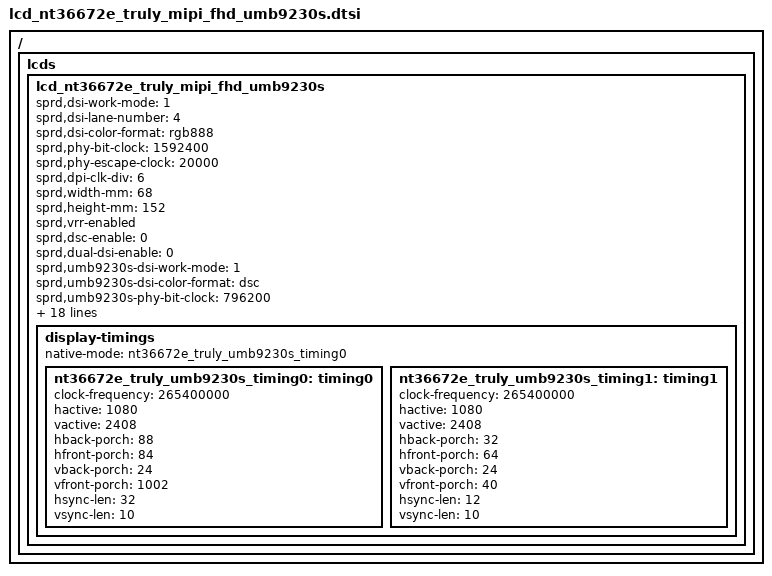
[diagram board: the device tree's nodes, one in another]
// SPDX-License-Identifier: GPL-2.0-only
/*
 * NT36672E TRULY config dtsi file for spreadtrum
 *
 * Copyright (C) 2021, Spreadtrum Communications Inc.
 */
/ {
	fragment {
		target-path = "/";
		__overlay__ {
			lcds {
				lcd_nt36672e_truly_mipi_fhd_umb9230s: lcd_nt36672e_truly_mipi_fhd_umb9230s {

					sprd,dsi-work-mode = <1>; /* video burst mode*/
					sprd,dsi-lane-number = <4>;
					sprd,dsi-color-format = "rgb888";

					sprd,phy-bit-clock = <1592400>;  /* kbps */
					sprd,phy-escape-clock = <20000>;/* kHz */

					sprd,dpi-clk-div = <6>;

					sprd,width-mm = <68>;
					sprd,height-mm = <152>;

					sprd,vrr-enabled;

					sprd,dsc-enable = <0>;
					sprd,dual-dsi-enable = <0>;

					sprd,umb9230s-dsi-work-mode = <1>; /* video burst mode*/
					sprd,umb9230s-dsi-color-format = "dsc";
					sprd,umb9230s-phy-bit-clock = <796200>;  /* kbps */
					sprd,umb9230s-dsc-enable = <1>;
					sprd,umb9230s-slice-width = <540>;
					sprd,umb9230s-slice-height = <8>;
					sprd,umb9230s-output-bpc = <8>;

					sprd,esd-check-enable = <1>;
					sprd,esd-check-mode = <0>;  // 0:Reg mode 1:TE mode
					sprd,esd-check-period = <1000>;
					sprd,esd-check-register = <0x0A>;
					sprd,esd-check-value = <0x9C>;

					sprd,reset-on-sequence = <1 15>, <0 15>, <1 15>;
					sprd,reset-off-sequence = <0 5>;

					sprd,use-gen-write;

					sprd,initial-command = [
						15 00 00 02 FF 10
						15 00 00 02 FB 01
						15 00 00 02 B0 00
						15 00 00 02 C0 03
						29 00 00 11 C1 89 28 00 08 02 00 02 0E 00 BB 00 07 0D B7 0C B7
						29 00 00 03 C2 12 18
						29 00 00 02 35 00

						15 00 00 02 FF 20
						15 00 00 02 FB 01
						15 00 00 02 01 66
						15 00 00 02 06 40
						15 00 00 02 07 38
						15 00 00 02 1B 01
						15 00 00 02 5C 90
						15 00 00 02 5E B2
						15 00 00 02 69 D1
						15 00 00 02 95 D1
						15 00 00 02 96 D1
						15 00 00 02 F2 64
						15 00 00 02 F4 64
						15 00 00 02 F6 64
						15 00 00 02 F8 64

						15 00 00 02 FF 24
						15 00 00 02 FB 01
						15 00 00 02 01 0F
						15 00 00 02 03 0C
						15 00 00 02 05 1D
						15 00 00 02 08 2F
						15 00 00 02 09 2E
						15 00 00 02 0A 2D
						15 00 00 02 0B 2C
						15 00 00 02 11 17
						15 00 00 02 12 13
						15 00 00 02 13 15
						15 00 00 02 15 14
						15 00 00 02 16 16
						15 00 00 02 17 18
						15 00 00 02 1B 01
						15 00 00 02 1D 1D
						15 00 00 02 20 2F
						15 00 00 02 21 2E
						15 00 00 02 22 2D
						15 00 00 02 23 2C
						15 00 00 02 29 17
						15 00 00 02 2A 13
						15 00 00 02 2B 15
						15 00 00 02 2F 14
						15 00 00 02 30 16
						15 00 00 02 31 18
						15 00 00 02 32 04
						15 00 00 02 34 10
						15 00 00 02 35 1F
						15 00 00 02 36 1F
						15 00 00 02 4D 19
						15 00 00 02 4E 45
						15 00 00 02 4F 45
						15 00 00 02 53 45
						15 00 00 02 71 30
						15 00 00 02 79 11
						15 00 00 02 7A 82
						15 00 00 02 7B 94
						15 00 00 02 7D 04
						15 00 00 02 80 04
						15 00 00 02 81 04
						15 00 00 02 82 13
						15 00 00 02 84 31
						15 00 00 02 85 00
						15 00 00 02 86 00
						15 00 00 02 87 00
						15 00 00 02 90 13
						15 00 00 02 92 31
						15 00 00 02 93 00
						15 00 00 02 94 00
						15 00 00 02 95 00
						15 00 00 02 9C F4
						15 00 00 02 9D 01
						15 00 00 02 A0 14
						15 00 00 02 A2 14
						15 00 00 02 A3 02
						15 00 00 02 A4 04
						15 00 00 02 A5 04
						15 00 00 02 C6 C0
						15 00 00 02 C9 00
						15 00 00 02 D9 80
						15 00 00 02 E9 02

						15 00 00 02 FF 25
						15 00 00 02 FB 01
						15 00 00 02 0F 1B
						15 00 00 02 19 E4
						15 00 00 02 21 40
						15 00 00 02 66 D8
						15 00 00 02 68 50
						15 00 00 02 69 10
						15 00 00 02 6B 00
						15 00 00 02 6D 0D
						15 00 00 02 6E 48
						15 00 00 02 72 41
						15 00 00 02 73 4A
						15 00 00 02 74 D0
						15 00 00 02 77 62
						15 00 00 02 7D 40
						15 00 00 02 7F 00
						15 00 00 02 80 04
						15 00 00 02 84 0D
						15 00 00 02 CF 80
						15 00 00 02 D6 80
						15 00 00 02 D7 80
						15 00 00 02 EF 20
						15 00 00 02 F0 84

						15 00 00 02 FF 26
						15 00 00 02 FB 01
						15 00 00 02 15 04
						15 00 00 02 81 14
						15 00 00 02 83 02
						15 00 00 02 84 03
						15 00 00 02 85 01
						15 00 00 02 86 03
						15 00 00 02 87 01
						15 00 00 02 88 06
						15 00 00 02 8A 1A
						15 00 00 02 8B 11
						15 00 00 02 8C 24
						15 00 00 02 8E 42
						15 00 00 02 8F 11
						15 00 00 02 90 11
						15 00 00 02 91 11
						15 00 00 02 9A 81
						15 00 00 02 9B 03
						15 00 00 02 9C 00
						15 00 00 02 9D 00
						15 00 00 02 9E 00

						15 00 00 02 FF 27
						15 00 00 02 FB 01
						15 00 00 02 01 68
						15 00 00 02 20 81
						15 00 00 02 21 E9
						15 00 00 02 25 82
						15 00 00 02 26 1E
						15 00 00 02 6E 00
						15 00 00 02 6F 00
						15 00 00 02 70 00
						15 00 00 02 71 00
						15 00 00 02 72 00
						15 00 00 02 75 00
						15 00 00 02 76 00
						15 00 00 02 77 00
						15 00 00 02 7D 09
						15 00 00 02 7E 67
						15 00 00 02 80 23
						15 00 00 02 82 09
						15 00 00 02 83 67
						15 00 00 02 88 01
						15 00 00 02 89 10
						15 00 00 02 A6 23
						15 00 00 02 A7 01
						15 00 00 02 B6 40

						15 00 00 02 FF 2A
						15 00 00 02 FB 01
						15 00 00 02 00 91
						15 00 00 02 03 20
						15 00 00 02 07 5A
						15 00 00 02 0A 70
						15 00 00 02 0D 40
						15 00 00 02 0E 02
						15 00 00 02 11 F0
						15 00 00 02 15 0F
						15 00 00 02 16 1A
						15 00 00 02 19 0E
						15 00 00 02 1A EE
						15 00 00 02 1B 14
						15 00 00 02 1D 36
						15 00 00 02 1E 4F
						15 00 00 02 1F 4F
						15 00 00 02 20 4F
						15 00 00 02 28 F7
						15 00 00 02 29 06
						15 00 00 02 2A 03
						15 00 00 02 2F 01
						15 00 00 02 30 45
						15 00 00 02 31 BD
						15 00 00 02 34 F9
						15 00 00 02 35 31
						15 00 00 02 36 05
						15 00 00 02 37 F4
						15 00 00 02 38 35
						15 00 00 02 39 01
						15 00 00 02 3A 45

						15 00 00 02 FF 2C
						15 00 00 02 FB 01
						15 00 00 02 00 02
						15 00 00 02 01 02
						15 00 00 02 02 02
						15 00 00 02 03 16
						15 00 00 02 04 16
						15 00 00 02 05 16
						15 00 00 02 0D 1F
						15 00 00 02 0E 1F
						15 00 00 02 16 1B
						15 00 00 02 17 4B
						15 00 00 02 18 4B
						15 00 00 02 19 4B
						15 00 00 02 2A 03
						15 00 00 02 4D 16
						15 00 00 02 4E 02
						15 00 00 02 4F 2F
						15 00 00 02 53 02
						15 00 00 02 54 02
						15 00 00 02 55 02
						15 00 00 02 56 0E
						15 00 00 02 58 0E
						15 00 00 02 59 0E
						15 00 00 02 61 1F
						15 00 00 02 62 1F
						15 00 00 02 6A 14
						15 00 00 02 6B 34
						15 00 00 02 6C 34
						15 00 00 02 6D 34
						15 00 00 02 7E 03
						15 00 00 02 9D 0E
						15 00 00 02 9E 02
						15 00 00 02 9F 02

						15 00 00 02 FF  20
						15 00 00 02 FB  01
						39 00 00 11 B0  00  00  00  15  00  3F  00  5F  00  7E  00  97  00  AF  00  C3
						39 00 00 11 B1  00  D7  01  0A  01  32  01  6F  01  9E  01  E5  02  1D  02  1E
						39 00 00 11 B2  02  56  02  94  02  BC  02  F1  03  13  03  41  03  4F  03  5F
						39 00 00 0f B3  03  71  03  84  03  99  03  B0  03  CA  03  D7  00  00
						39 00 00 11 B4  00  00  00  17  00  46  00  69  00  8C  00  A5  00  BE  00  D1
						39 00 00 11 B5  00  E4  01  18  01  40  01  7C  01  AA  01  F0  02  27  02  28
						39 00 00 11 B6  02  5E  02  9B  02  C3  02  F6  03  18  03  45  03  54  03  63
						39 00 00 0f B7  03  75  03  87  03  9C  03  B2  03  CA  03  D7  00  00
						39 00 00 11 B8  00  00  00  18  00  49  00  6B  00  8E  00  A8  00  C1  00  D3
						39 00 00 11 B9  00  E5  01  18  01  3F  01  7B  01  A8  01  EC  02  24  02  26
						39 00 00 11 BA  02  5A  02  97  02  C0  02  F4  03  15  03  43  03  51  03  61
						39 00 00 0f BB  03  72  03  85  03  9A  03  B1  03  CA  03  D7  00  00
						15 00 00 02 C6 00
						15 00 00 02 C7 00
						15 00 00 02 C8 00
						15 00 00 02 C9 00
						15 00 00 02 CA 00

						15 00 00 02 CB 00
						15 00 00 02 CC 00
						15 00 00 02 CD 00
						15 00 00 02 CE 00
						15 00 00 02 CF 00

						15 00 00 02 D0 00
						15 00 00 02 D1 00
						15 00 00 02 D2 00
						15 00 00 02 D3 00
						15 00 00 02 D4 00

						15 00 00 02 D5 00
						15 00 00 02 D6 00
						15 00 00 02 D7 00
						15 00 00 02 D8 00
						15 00 00 02 D9 00

						15 00 00 02 DA 00
						15 00 00 02 DB 00
						15 00 00 02 DC 00
						15 00 00 02 DD 00
						15 00 00 02 DE 00

						15 00 00 02 DF 00
						15 00 00 02 E0 00
						15 00 00 02 E1 00
						15 00 00 02 E2 00
						15 00 00 02 E3 00

						15 00 00 02 E4 00

						15 00 00 02 E5 00

						15 00 00 02 E6 00

						15 00 00 02 E7 00

						15 00 00 02 E8 00

						15 00 00 02 E9 00

						15 00 00 02 FF  21
						15 00 00 02 FB  01
						39 00 00 11 B0  00  00  00  15  00  3F  00  5F  00  7E  00  97  00  AF  00  C3
						39 00 00 11 B1  00  D7  01  0A  01  32  01  6F  01  9E  01  E5  02  1D  02  1E
						39 00 00 11 B2  02  56  02  94  02  BC  02  F1  03  13  03  41  03  4F  03  5F
						39 00 00 0f B3  03  71  03  84  03  99  03  B0  03  CA  03  D7  00  00
						39 00 00 11 B4  00  00  00  17  00  46  00  69  00  8C  00  A5  00  BE  00  D1
						39 00 00 11 B5  00  E4  01  18  01  40  01  7C  01  AA  01  F0  02  27  02  28
						39 00 00 11 B6  02  5E  02  9B  02  C3  02  F6  03  18  03  45  03  54  03  63
						39 00 00 0f B7  03  75  03  87  03  9C  03  B2  03  CA  03  D7  00  00
						39 00 00 11 B8  00  00  00  18  00  49  00  6B  00  8E  00  A8  00  C1  00  D3
						39 00 00 11 B9  00  E5  01  18  01  3F  01  7B  01  A8  01  EC  02  24  02  26
						39 00 00 11 BA  02  5A  02  97  02  C0  02  F4  03  15  03  43  03  51  03  61
						39 00 00 0f BB  03  72  03  85  03  9A  03  B1  03  CA  03  D7  00  00

						15 00 00 02 FF E0
						15 00 00 02 FB 01
						15 00 00 02 35 82

						15 00 00 02 FF F0
						15 00 00 02 FB 01
						15 00 00 02 1C 01
						15 00 00 02 33 01
						15 00 00 02 5A 00
						15 00 00 02 D2 52

						15 00 00 02 FF D0
						15 00 00 02 FB 01
						15 00 00 02 53 22
						15 00 00 02 54 02

						15 00 00 02 FF C0
						15 00 00 02 FB 01
						15 00 00 02 9C 11
						15 00 00 02 9D 11

						15 00 00 02 FF 2B
						15 00 00 02 FB 01
						15 00 00 02 B7 1A
						15 00 00 02 B8 1D
						15 00 00 02 C0 01

						15 00 00 02 FF 10
						05 C8 00 01 11
						05 32 00 01 29
						];

					sprd,sleep-in-command = [
						13 0A 00 01 28
						13 78 00 01 10
						23 0a 00 02 4f 01
						];
					sprd,sleep-out-command = [
						13 78 00 01 11
						13 32 00 01 29
						];

					display-timings {
						native-mode = <&nt36672e_truly_umb9230s_timing0>;

						nt36672e_truly_umb9230s_timing0: timing0 {
							clock-frequency = <265400000>;
							hactive = <1080>;
							vactive = <2408>; /*2408*/
							hback-porch = <88>;
							hfront-porch = <84>;
							vback-porch = <24>;
							vfront-porch = <1002>;
							hsync-len = <32>;
							vsync-len = <10>;
						};

						nt36672e_truly_umb9230s_timing1: timing1 {
							clock-frequency = <265400000>;
							hactive = <1080>;
							vactive = <2408>; /*2408*/
							hback-porch = <32>;
							hfront-porch = <64>;
							vback-porch = <24>;
							vfront-porch = <40>;
							hsync-len = <12>;
							vsync-len = <10>;
						};
					};
				};
			};
		};
	};
};
